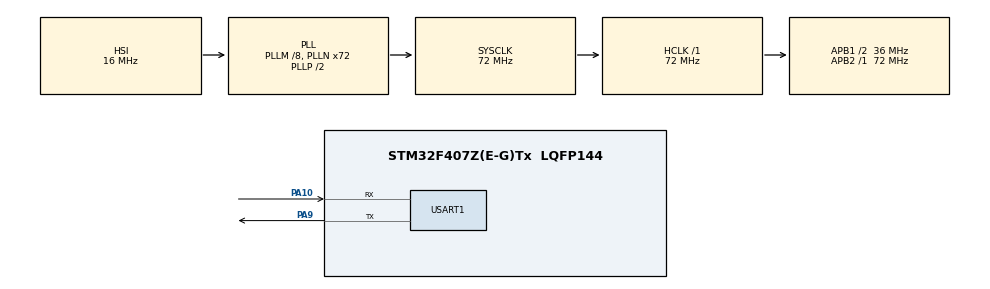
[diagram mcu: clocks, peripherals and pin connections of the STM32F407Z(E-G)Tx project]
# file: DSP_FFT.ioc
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Mcu.Family=STM32F4
Mcu.Name=STM32F407Z(E-G)Tx
Mcu.Package=LQFP144
NVIC.PriorityGroup=NVIC_PRIORITYGROUP_4
PA10.Mode=Asynchronous
PA10.Signal=USART1_RX
PA9.Mode=Asynchronous
PA9.Signal=USART1_TX
PC14-OSC32_IN.Mode=LSE-External-Oscillator
PC14-OSC32_IN.Signal=RCC_OSC32_IN
PC15-OSC32_OUT.Mode=LSE-External-Oscillator
PC15-OSC32_OUT.Signal=RCC_OSC32_OUT
PH0-OSC_IN.Mode=HSE-External-Oscillator
PH0-OSC_IN.Signal=RCC_OSC_IN
PH1-OSC_OUT.Mode=HSE-External-Oscillator
PH1-OSC_OUT.Signal=RCC_OSC_OUT
ProjectManager.HeapSize=0x200
ProjectManager.StackSize=0x400
ProjectManager.TargetToolchain=MDK-ARM V5.32
RCC.48MHZClocksFreq_Value=36000000
RCC.AHBFreq_Value=72000000
RCC.APB1CLKDivider=RCC_HCLK_DIV2
RCC.APB1Freq_Value=36000000
RCC.APB1TimFreq_Value=72000000
RCC.APB2Freq_Value=72000000
RCC.APB2TimFreq_Value=72000000
RCC.CortexFreq_Value=72000000
RCC.HCLKFreq_Value=72000000
RCC.HSE_VALUE=25000000
RCC.HSI_VALUE=16000000
RCC.PLLM=8
RCC.PLLN=72
RCC.SYSCLKFreq_VALUE=72000000
RCC.SYSCLKSource=RCC_SYSCLKSOURCE_PLLCLK
RCC.VCOOutputFreq_Value=144000000
USART1.VirtualMode=VM_ASYNC
board=custom

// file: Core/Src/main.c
/* USER CODE BEGIN Header */
/**
  ******************************************************************************
  * @file           : main.c
  * @brief          : Main program body
  ******************************************************************************
  * @attention
  *
  * Copyright (c) 2024 STMicroelectronics.
  * All rights reserved.
  *
  * This software is licensed under terms that can be found in the LICENSE file
  * in the root directory of this software component.
  * If no LICENSE file comes with this software, it is provided AS-IS.
  *
  ******************************************************************************
  */
/* USER CODE END Header */
#include "main.h"
#include "usart.h"
#include "gpio.h"

/* USER CODE BEGIN Includes */
#include <stdio.h>
#include "arm_math.h"
#include "arm_const_structs.h"
/* USER CODE END Includes */

/* USER CODE BEGIN PD */
#define FFT_LEN 1024
/* USER CODE END PD */

/* USER CODE BEGIN PM */
int fputc(int ch,FILE *f)
{
    uint8_t temp[1]={ch};
    HAL_UART_Transmit(&huart1, temp, 1, 2);
	return ch;
}
/* USER CODE END PM */

/* USER CODE BEGIN PV */

float data[FFT_LEN];
// input
float data_in[FFT_LEN * 2];//复数，实部和虚部
// output
float data_out[FFT_LEN];
/* USER CODE END PV */

void SystemClock_Config(void);

int main(void)
{

  /* USER CODE BEGIN 1 */
  int i = 0;
  /* USER CODE END 1 */

  /* MCU Configuration--------------------------------------------------------*/

  /* Reset of all peripherals, Initializes the Flash interface and the Systick. */
  HAL_Init();

  /* Configure the system clock */
  SystemClock_Config();

  /* Initialize all configured peripherals */
  MX_GPIO_Init();
  MX_USART1_UART_Init();
  /* USER CODE BEGIN 2 */
	for(i = 0; i < FFT_LEN; i++){
		data[i] = 5 * sin(2 * 3.14 / FFT_LEN * i) + sin(200 * 3.14 / FFT_LEN *i);
	}
  /* USER CODE END 2 */

  /* Infinite loop */
  /* USER CODE BEGIN WHILE */
  while (1)
  {
		for(i = 0; i < FFT_LEN; i++){
	    data_in[i * 2] = data[i];//实部
		  data_in[i * 2 + 1] = 0;//虚部
	  }

		arm_cfft_f32(&arm_cfft_sR_f32_len1024, data_in, 0, 1);

		arm_cmplx_mag_f32(data_in, data_out, FFT_LEN);
    /* USER CODE END WHILE */

    /* USER CODE BEGIN 3 */
		data_out[0] /= FFT_LEN;
		for(i = 0; i < FFT_LEN; i++){
		  data_out[i] /= (FFT_LEN/2);
		}

		for (int i = 0; i < FFT_LEN; i++){
	    printf("%d:\t%.2f\r\n", i, data_out[i]);
    }
	  HAL_Delay(5000);
  }
  /* USER CODE END 3 */
}

void SystemClock_Config(void)
{
  RCC_OscInitTypeDef RCC_OscInitStruct = {0};
  RCC_ClkInitTypeDef RCC_ClkInitStruct = {0};

  /** Configure the main internal regulator output voltage
  */
  __HAL_RCC_PWR_CLK_ENABLE();
  __HAL_PWR_VOLTAGESCALING_CONFIG(PWR_REGULATOR_VOLTAGE_SCALE1);

  /** Initializes the RCC Oscillators according to the specified parameters
  * in the RCC_OscInitTypeDef structure.
  */
  RCC_OscInitStruct.OscillatorType = RCC_OSCILLATORTYPE_HSI;
  RCC_OscInitStruct.HSIState = RCC_HSI_ON;
  RCC_OscInitStruct.HSICalibrationValue = RCC_HSICALIBRATION_DEFAULT;
  RCC_OscInitStruct.PLL.PLLState = RCC_PLL_ON;
  RCC_OscInitStruct.PLL.PLLSource = RCC_PLLSOURCE_HSI;
  RCC_OscInitStruct.PLL.PLLM = 8;
  RCC_OscInitStruct.PLL.PLLN = 72;
  RCC_OscInitStruct.PLL.PLLP = RCC_PLLP_DIV2;
  RCC_OscInitStruct.PLL.PLLQ = 4;
  if (HAL_RCC_OscConfig(&RCC_OscInitStruct) != HAL_OK)
  {
    Error_Handler();
  }

  /** Initializes the CPU, AHB and APB buses clocks
  */
  RCC_ClkInitStruct.ClockType = RCC_CLOCKTYPE_HCLK|RCC_CLOCKTYPE_SYSCLK
                              |RCC_CLOCKTYPE_PCLK1|RCC_CLOCKTYPE_PCLK2;
  RCC_ClkInitStruct.SYSCLKSource = RCC_SYSCLKSOURCE_PLLCLK;
  RCC_ClkInitStruct.AHBCLKDivider = RCC_SYSCLK_DIV1;
  RCC_ClkInitStruct.APB1CLKDivider = RCC_HCLK_DIV2;
  RCC_ClkInitStruct.APB2CLKDivider = RCC_HCLK_DIV1;

  if (HAL_RCC_ClockConfig(&RCC_ClkInitStruct, FLASH_LATENCY_2) != HAL_OK)
  {
    Error_Handler();
  }
}

void Error_Handler(void)
{
  __disable_irq();
  while (1)
  {
  }
}
